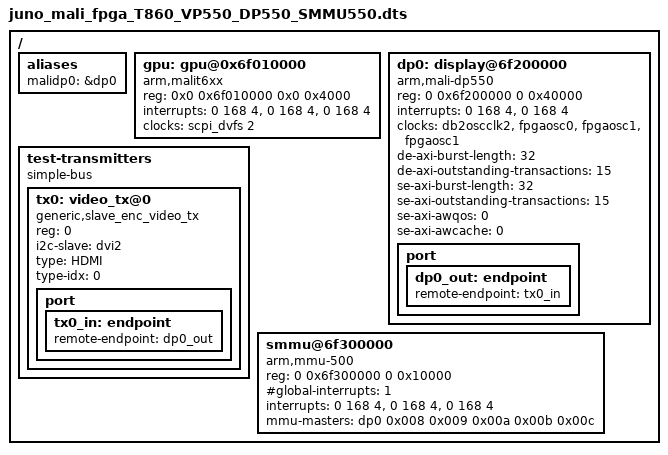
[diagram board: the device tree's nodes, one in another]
/*
 * ARM Ltd. Juno Plaform
 *
 * Fast Models FVP v2 support
 */

#include "juno-common.dtsi"

/ {
	aliases {
		malidp0 = &dp0;
	};

	gpu: gpu@0x6f010000 {
		compatible = "arm,malit6xx", "arm,mali";
		reg = <0x0 0x6f010000 0x0 0x4000>;
		interrupts = <0 168 4>, <0 168 4>, <0 168 4>;
		interrupt-names = "JOB", "MMU", "GPU";
		clocks = <&scpi_dvfs 2>;
		clock-names = "clk_mali";
	};

	dp0: display@6f200000 {
		compatible = "arm,mali-dp550";
		reg = <0 0x6f200000 0 0x40000>;
		interrupts = <0 168 4>, <0 168 4>;
		interrupt-names = "DE", "SE";
		clocks = <&db2oscclk2>, <&fpgaosc0>, <&fpgaosc1>, <&fpgaosc1>;
		clock-names = "pxclk", "mclk", "aclk", "pclk";
		de-axi-burst-length = <32>;
		de-axi-outstanding-transactions = <15>;
		se-axi-burst-length = <32>;
		se-axi-outstanding-transactions = <15>;
		se-axi-awqos = <0>;
		se-axi-awcache = <0>;
		#stream-id-cells = <5>;
		port {
			dp0_out: endpoint {
				remote-endpoint = <&tx0_in>;
			};
		};
	};

	test-transmitters {
		compatible = "simple-bus";
		#address-cells = <1>;
		#size-cells = <0>;

		tx0: video_tx@0 {
			compatible = "generic,slave_enc_video_tx";
			reg = <0>;
			i2c-slave = <&dvi2>;
			type = "HDMI";
			type-idx = <0>;
			port {
				tx0_in: endpoint {
					remote-endpoint = <&dp0_out>;
				};
			};
		};
	};

	smmu@6f300000 {
		compatible = "arm,mmu-500";
		reg = <0 0x6f300000 0 0x10000>;
		#global-interrupts = <1>;
		interrupts = <0 168 4>, <0 168 4>, <0 168 4>;
		mmu-masters = <&dp0 0x008 0x009 0x00a 0x00b 0x00c>;
	};
};
